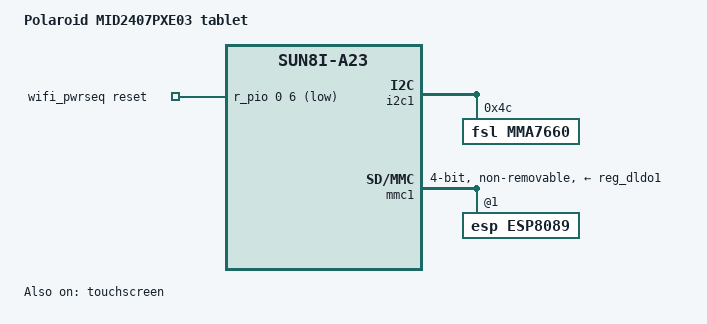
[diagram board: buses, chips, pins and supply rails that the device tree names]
/dts-v1/;
#include "sun8i-a23.dtsi"
#include "sun8i-reference-design-tablet.dtsi"
/ {
	model = "Polaroid MID2407PXE03 tablet";
	compatible = "polaroid,mid2407pxe03", "allwinner,sun8i-a23";
	aliases {
		ethernet0 = &esp8089;
	};
	wifi_pwrseq: wifi_pwrseq {
		compatible = "mmc-pwrseq-simple";
		reset-gpios = <&r_pio 0 6 GPIO_ACTIVE_LOW>;  
		post-power-on-delay-ms = <200>;
	};
};
&i2c1 {
	mma7660: accelerometer@4c {
		reg = <0x4c>;
		compatible = "fsl,mma7660";
	};
};
&mmc1 {
	pinctrl-names = "default";
	pinctrl-0 = <&mmc1_pg_pins>;
	vmmc-supply = <&reg_dldo1>;
	mmc-pwrseq = <&wifi_pwrseq>;
	bus-width = <4>;
	non-removable;
	status = "okay";
	esp8089: sdio_wifi@1 {
		compatible = "esp,esp8089";
		reg = <1>;
		esp,crystal-26M-en = <2>;
	};
};
&touchscreen {
	reg = <0x40>;
	compatible = "silead,gsl1680";
	firmware-name = "gsl1680-polaroid-mid2407pxe03.fw";
	touchscreen-size-x = <960>;
	touchscreen-size-y = <640>;
	touchscreen-inverted-x;
	touchscreen-inverted-y;
	vddio-supply = <&reg_ldo_io1>;
	status = "okay";
};
